# CMS32M67xx register map
Vendor: CMS; Series: CMS32M67xx; File version: 1.2
CPU: CM0+ r0p1, little endian, no MPU, no FPU, VTOR, 2 interrupt priority bits
Registers are 32-bit, read-write, reset 0x0 unless marked. A register's access mark holds for its fields unless they carry their own. Offsets are from the block's base; [hi:lo] are bit positions; {n}, {i} and the like mark numbered series.

## HALL — HALL Decription
Base 0x40064500
0x00 CFG — Config register
0x04 INFO ro — Information Description
0x08 CLRF wo — Interrupt flag clear register
0x0C WIDTH ro — HALL width register
0x10 TH — HALL count limit register
0x14 CNT — HALL Counter

## UART0 — UART0 Decription
Base 0x40064000
0x00 UART0RBR ro — UART0RBR Description
0x04 UART0THR wo — UART0THR Description
0x08 UART0DLR reset 0x1 — UART0DLR Description
0x0C UART0IER — UART0IER Description
0x10 UART0IIR ro reset 0x1 — UART0IIR Description
0x18 UART0LCR — UART0LCR Description
0x1C UART0MCR — UART0MCR Description
0x20 UART0LSR ro reset 0x60 — UART0LSR Description

## UART1 — UART1 Decription
Base 0x40064100
Registers as UART0 (with UART0 read as UART1).

## IICA — Serial Interface I2C with multimaster and wakeup supported
Base 0x40041A30
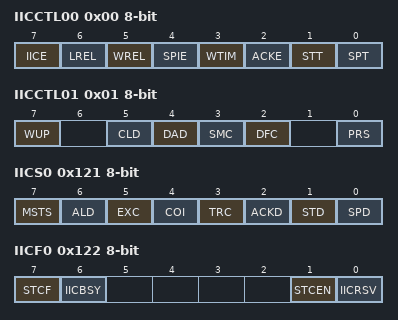
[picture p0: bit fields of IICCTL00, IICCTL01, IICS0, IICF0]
0x00 IICCTL00 8-bit — IICA control register 0
  [7] IICE — I2C operation enable
  [6] LREL — Exit from communications
  [5] WREL — Wait cancellation
  [4] SPIE — Enable generation of interrupt request when stop condition is detected
  [3] WTIM — Control of wait and interrupt request generation
  [2] ACKE — Acknowledgment control
  [1] STT — Start condition trigger
  [0] SPT — Stop condition trigger
0x01 IICCTL01 8-bit — IICA control register 0
  [7] WUP — Control of address match wakeup
  [5] CLD ro — Detection of SCLAn pin level (valid only when IICEn = 1)
  [4] DAD ro — Detection of SDAAn pin level (valid only when IICEn = 1)
  [3] SMC — Operation mode switching
  [2] DFC — Digital filter operation control
  [0] PRS — Operation clock (fMCK) contro
0x02 IICWL0 8-bit reset 0xFF — IICA low-level width setting register 0
0x03 IICWH0 8-bit reset 0xFF — IICA high-level width setting register 0
0x120 IICA0 8-bit — IICA shift register 0
0x121 IICS0 8-bit ro — IICA status register 0
  [7] MSTS — Master status check flag
  [6] ALD — Detection of arbitration loss
  [5] EXC — Detection of extension code reception
  [4] COI — Detection of matching addresses
  [3] TRC — Detection of transmit/receive status
  [2] ACKD — Detection of acknowledge (ACK)
  [1] STD — Detection of start condition
  [0] SPD — Detection of stop condition
0x122 IICF0 8-bit — IICA flag register 0
  [7] STCF ro — STT clear flag
  [6] IICBSY ro — I2C bus status flag
  [1] STCEN — Initial start enable trigger
  [0] IICRSV — Communication reservation function disable bit

## SSP0 — SSP0 Decription
Base 0x40063000
0x00 SSPCON — SSPCON Description
0x04 SSPSTAT ro reset 0x3 — SSPSTAT Description
0x08 SSPDAT — SSPDAT Description
0x0C SSPCLK — SSPCLK Description
0x10 SSPIMSC — SSPIMSC Description
0x14 SSPRIS ro reset 0x8 — SSPRIS Description
0x18 SSPMIS ro — SSPMIS Description
0x1C SSPICLR wo — SSPICLR Description
0x28 SSPCSCR — SSPCSCR Description

## ADC — ADC Decription
Base 0x40068000
0x00 ADCCON — ADCCON Description
0x04 ADCCON2 — ADCCON2 Description
0x08 ADCHWTG — ADCHWTG Description
0x0C ADCPWMTGDLY — ADCPWMTGDLY Description
0x10 ADCSCAN — ADCSCAN Description
0x14 ADCCMP0 — ADCCMP0 Description
0x18 ADCCMP1 — ADCCMP1 Description
0x1C ADCIMSC — ADCIMSC Description
0x20 ADCRIS ro — ADCRIS Description
0x24 ADCMIS ro — ADCMIS Description
0x28 ADCICLR wo — ADCICLR Description
0x2C ADCLOCK — ADCLOCK Description
0x30 ADCCHEPWM — ADCCHEPWM Description
0x34 ADCCHPTG0 — ADCCHPTG0 Description
0x38 ADCCHPTG1 — ADCCHPTG1 Description
0x3C ADCCHPIFTG — ADCCHPIFTG Description
0x40 ADCCHZIFTG — ADCCHZIFTG Description
0x48 ADCTEST — ADCTEST Description
0x50 ADCRESULT — ADCRESULT Description
{0x80+4i} ADCDATA{i} ro (i=0..26) — ADCDATA{i} Description
